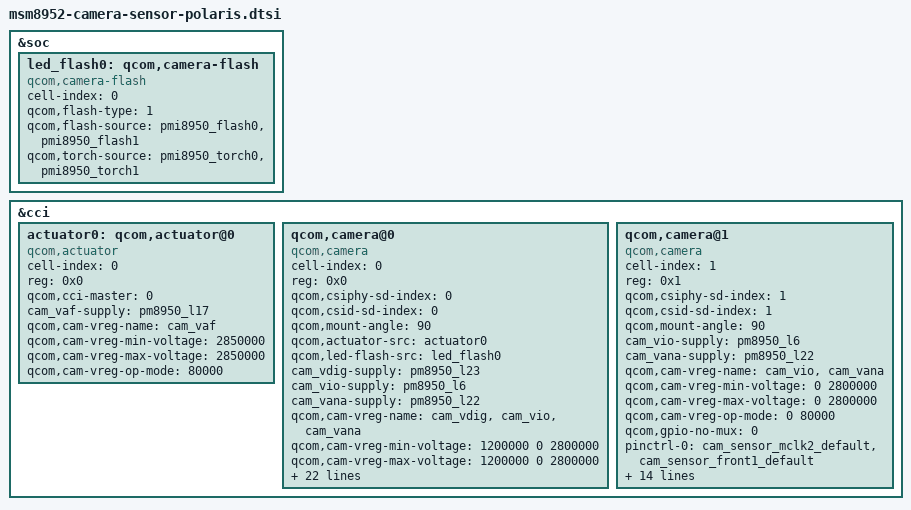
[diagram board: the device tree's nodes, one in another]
/*
 * Copyright (c) 2015, The Linux Foundation. All rights reserved.
 *
 * This program is free software; you can redistribute it and/or modify
 * it under the terms of the GNU General Public License version 2 and
 * only version 2 as published by the Free Software Foundation.
 *
 * This program is distributed in the hope that it will be useful,
 * but WITHOUT ANY WARRANTY; without even the implied warranty of
 * MERCHANTABILITY or FITNESS FOR A PARTICULAR PURPOSE.  See the
 * GNU General Public License for more details.
 */

&soc {
	led_flash0: qcom,camera-flash {
		cell-index = <0>;
		compatible = "qcom,camera-flash";
		qcom,flash-type = <1>;
		qcom,flash-source = <&pmi8950_flash0 &pmi8950_flash1>;
		qcom,torch-source = <&pmi8950_torch0 &pmi8950_torch1>;
	};
};

&cci {
	actuator0: qcom,actuator@0 {
		cell-index = <0>;
		reg = <0x0>;
		compatible = "qcom,actuator";
		qcom,cci-master = <0>;
		cam_vaf-supply = <&pm8950_l17>;
		qcom,cam-vreg-name = "cam_vaf";
		qcom,cam-vreg-min-voltage = <2850000>;
		qcom,cam-vreg-max-voltage = <2850000>;
		qcom,cam-vreg-op-mode = <80000>;
	};

	qcom,camera@0 {
		cell-index = <0>;
		compatible = "qcom,camera";
		reg = <0x0>;
		qcom,csiphy-sd-index = <0>;
		qcom,csid-sd-index = <0>;
		qcom,mount-angle = <90>;
		qcom,actuator-src = <&actuator0>;
		qcom,led-flash-src = <&led_flash0>;
		cam_vdig-supply = <&pm8950_l23>;
		cam_vio-supply = <&pm8950_l6>;
		cam_vana-supply = <&pm8950_l22>;
		qcom,cam-vreg-name = "cam_vdig", "cam_vio", "cam_vana";
		qcom,cam-vreg-min-voltage = <1200000 0 2800000>;
		qcom,cam-vreg-max-voltage = <1200000 0 2800000>;
		qcom,cam-vreg-op-mode = <200000 0 80000>;
		qcom,gpio-no-mux = <0>;
		pinctrl-names = "cam_default", "cam_suspend";
		pinctrl-0 = <&cam_sensor_mclk0_default
			    &cam_sensor_rear_default
			    &cam_sensor_rear_vaf_default>;
		pinctrl-1 = <&cam_sensor_mclk0_sleep
			    &cam_sensor_rear_sleep
			    &cam_sensor_rear_vaf_sleep>;
		gpios = <&msm_gpio 26 0>,
			<&msm_gpio 36 0>,
			<&msm_gpio 35 0>,
			<&msm_gpio 6 0>;
		qcom,gpio-reset = <1>;
		qcom,gpio-standby = <2>;
		qcom,gpio-af-pwdm = <3>;
		qcom,gpio-req-tbl-num = <0 1 2 3>;
		qcom,gpio-req-tbl-flags = <1 0 0 0>;
		qcom,gpio-req-tbl-label = "CAMIF_MCLK0",
			"CAM_RESET0",
			"CAM_STANDBY0",
			"CAM_AF_PWDM0";
		qcom,sensor-position = <0>;
		qcom,sensor-mode = <0>;
		qcom,cci-master = <0>;
		status = "ok";
		clocks = <&clock_gcc clk_mclk0_clk_src>,
				<&clock_gcc clk_gcc_camss_mclk0_clk>;
		clock-names = "cam_src_clk", "cam_clk";
	};

	qcom,camera@1 {
		cell-index = <1>;
		compatible = "qcom,camera";
		reg = <0x1>;
		qcom,csiphy-sd-index = <1>;
		qcom,csid-sd-index = <1>;
		qcom,mount-angle = <90>;
		cam_vio-supply = <&pm8950_l6>;
		cam_vana-supply = <&pm8950_l22>;
		qcom,cam-vreg-name = "cam_vio", "cam_vana";
		qcom,cam-vreg-min-voltage = <0 2800000>;
		qcom,cam-vreg-max-voltage = <0 2800000>;
		qcom,cam-vreg-op-mode = <0 80000>;
		qcom,gpio-no-mux = <0>;
		pinctrl-names = "cam_default", "cam_suspend";
		pinctrl-0 = <&cam_sensor_mclk2_default
			    &cam_sensor_front1_default>;
		pinctrl-1 = <&cam_sensor_mclk2_sleep
			    &cam_sensor_front1_sleep>;
		gpios = <&msm_gpio 28 0>,
			<&msm_gpio 40 0>,
			<&msm_gpio 39 0>;
		qcom,gpio-reset = <1>;
		qcom,gpio-standby = <2>;
		qcom,gpio-req-tbl-num = <0 1 2>;
		qcom,gpio-req-tbl-flags = <1 0 0>;
		qcom,gpio-req-tbl-label = "CAMIF_MCLK2",
					  "CAM_RESET2",
					  "CAM_STANDBY2";
		qcom,sensor-position = <1>;
		qcom,sensor-mode = <0>;
		qcom,cci-master = <0>;
		status = "ok";
		clocks = <&clock_gcc clk_mclk2_clk_src>,
			<&clock_gcc clk_gcc_camss_mclk2_clk>;
		clock-names = "cam_src_clk", "cam_clk";
	};
};
